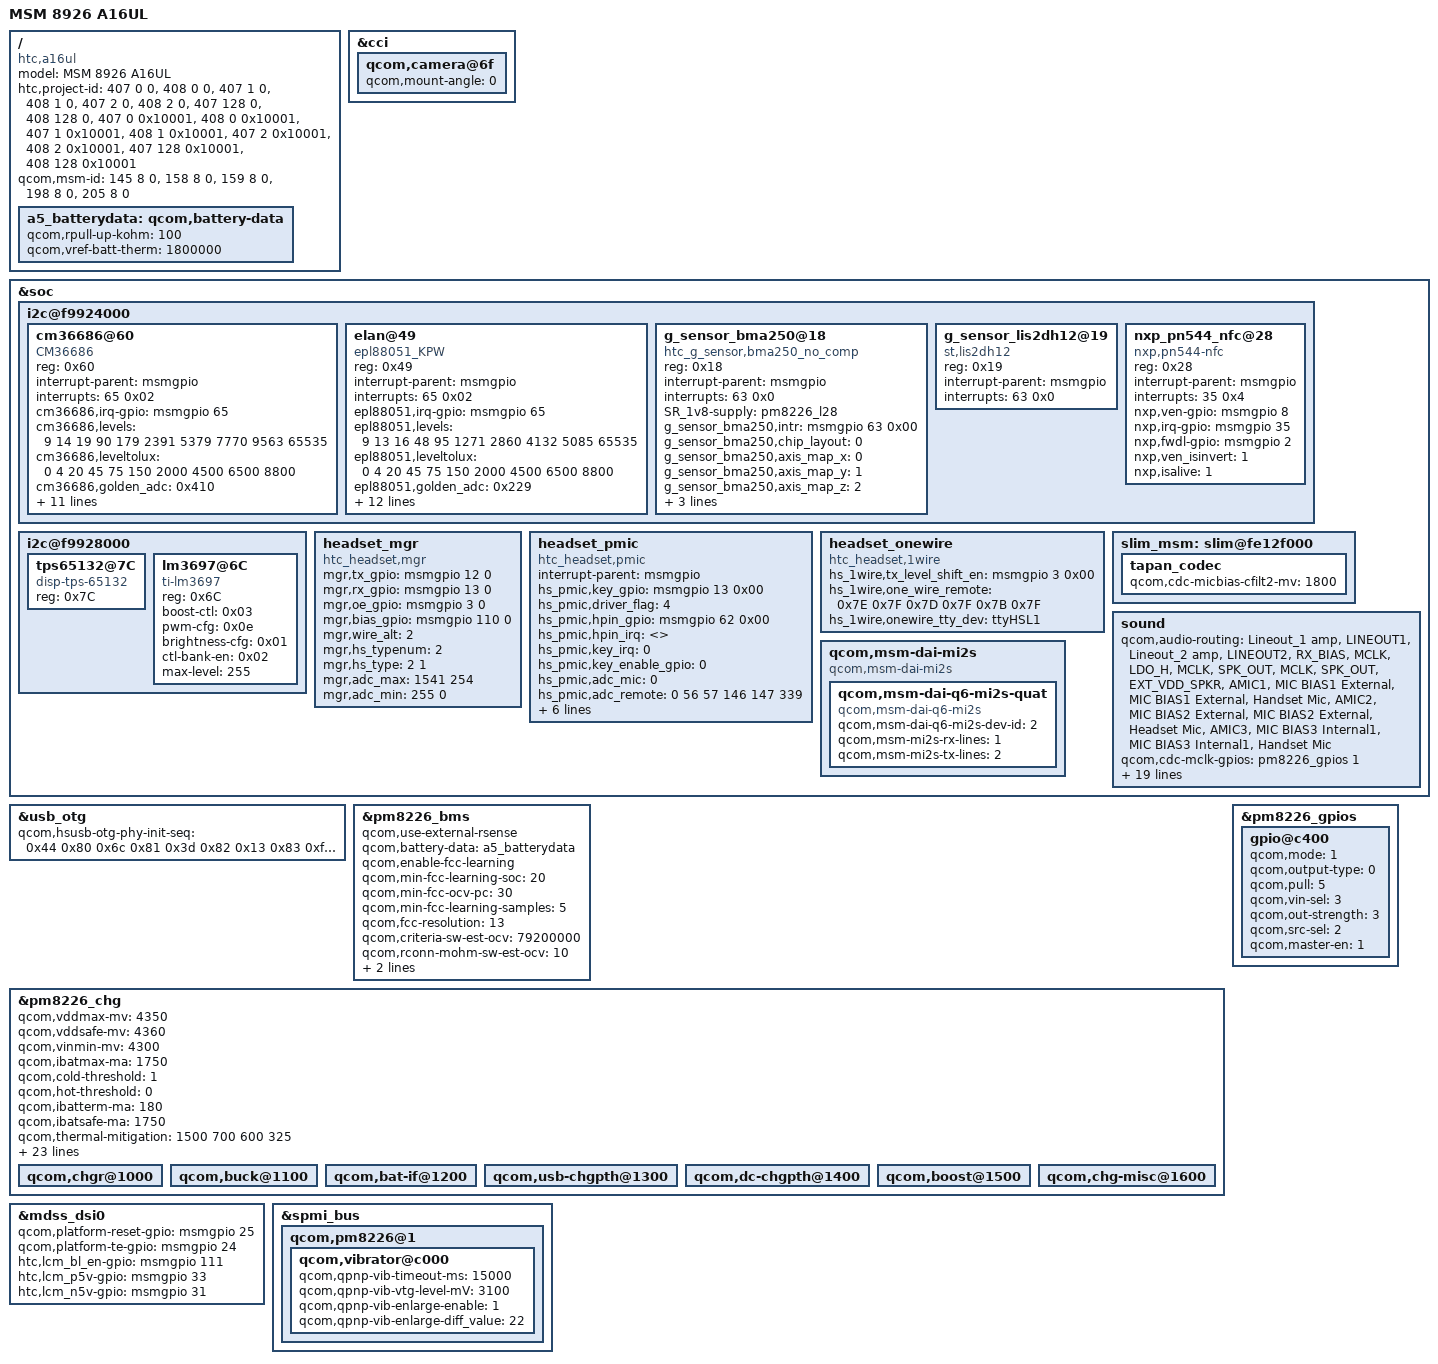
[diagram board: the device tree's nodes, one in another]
/* Copyright (c) 2013, The Linux Foundation. All rights reserved.
 *
 * This program is free software; you can redistribute it and/or modify
 * it under the terms of the GNU General Public License version 2 and
 * only version 2 as published by the Free Software Foundation.
 *
 * This program is distributed in the hope that it will be useful,
 * but WITHOUT ANY WARRANTY; without even the implied warranty of
 * MERCHANTABILITY or FITNESS FOR A PARTICULAR PURPOSE.  See the
 * GNU General Public License for more details.
 */

/dts-v1/;
/include/ "msm8926.dtsi"
/include/ "msm8226-720p-mtp.dtsi"
/*/include/ "msm-ncp6924.dtsi"*/
/include/ "dsi-panel-a16.dtsi"
/include/ "msm8226-a5ul-storage.dtsi"
/include/ "msm8926-touch-a16-config.dtsi"
/include/ "msm8926-flashlight-a16.dtsi"
/include/ "msm8926-key-a16.dtsi"
/include/ "msm8926-a16ul-twl80125-regulator.dtsi"

/ {
	model = "MSM 8926 A16UL";
	compatible = "htc,a16ul", "qcom,msm8926-mtp", "qcom,msm8926", "qcom,mtp";
	htc,project-id = <407 0 0>, <408 0 0>, <407 1 0>, <408 1 0>, <407 2 0>, <408 2 0>, <407 128 0>, <408 128 0>, <407 0 0x10001>, <408 0 0x10001>, <407 1 0x10001>, <408 1 0x10001>, <407 2 0x10001>, <408 2 0x10001>, <407 128 0x10001>, <408 128 0x10001>;  /* <pid hw-version reserve> */
	qcom,msm-id = <145 8 0>,
		      <158 8 0>,
		      <159 8 0>,
		      <198 8 0>,
		      <205 8 0>;
};

&cci {
	/* Rotate rear camera to 0 degrees */
	qcom,camera@6f {
	qcom,mount-angle = <0>;
	};
};

&soc {
	i2c@f9924000 {
		cm36686@60 {
			compatible = "CM36686";
			reg = <0x60>;
			// MSM8909: msm_gpio, MSM8928: msmgpio
			interrupt-parent = <&msmgpio>;
			interrupts = <65 0x02>;
			interrupt-names = "cm36686";
			cm36686,irq-gpio = <&msmgpio 65 0x00>;
			cm36686,levels = <9 14 19 90 179 2391 5379 7770 9563 65535>;
			cm36686,leveltolux = <0 4 20 45 75 150 2000 4500 6500 8800>;
			cm36686,golden_adc = <0x410>;
			cm36686,cm36686_slave_address = <0x60>;
			cm36686,ps1_thd_set = <0x15>;
			cm36686,ps1_thd_no_cal = <0xAAA>;
			cm36686,dynamical_threshold = <1>;
			cm36686,dark_level = <3>;
			cm36686,ps_duty = <0>;
			cm36686,ps_pers = <1>;
			cm36686,ps_it = <7>;
			cm36686,ps_hd = <0>;
			cm36686,ps_led_current = <2>;
			SR_2v85-supply = <&pm8226_l19>;
		};
	};

	i2c@f9924000 {
		elan@49 {
			compatible = "epl88051_KPW";
			reg = <0x49>;
			/* MSM8909: msm_gpio; MSM8928: msmgpio */
			interrupt-parent = <&msmgpio>;
			interrupts = <65 0x02>;
			interrupt-names = "epl88051";
			epl88051,irq-gpio = <&msmgpio 65 0x00>;
			epl88051,levels = <9 13 16 48 95 1271 2860 4132 5085 65535>;
			epl88051,leveltolux = <0 4 20 45 75 150 2000 4500 6500 8800>;
			epl88051,golden_adc = <0x229>;
			epl88051,epl88051_slave_address = <0x49>;
			epl88051,ps1_thd_set = <0x15>;
			epl88051,ps_th_add = <0x1F4>;
			epl88051,ps1_thd_no_cal = <0xAAA>;
			epl88051,dynamical_threshold = <1>;
			epl88051,dark_level = <3>;
			epl88051,ps_duty = <0x06>; //PS_FILTER(ps 64 cycle)
			epl88051,ps_pers = <0x00>; //PS_PERSIST(1 frame)
			epl88051,ps_it = <0x18>; //PS_INTEG (INTEG=80)
			epl88051,ps_hd = <0>;
			epl88051,ps_led_current = <0x00>; //PS_IR_DRIVE(200mA)
			SR_2v85-supply = <&pm8226_l19>;
	        };
	};

	i2c@f9924000 {
		g_sensor_bma250@18 {
			compatible = "htc_g_sensor,bma250_no_comp";
			reg = <0x18>;
			interrupt-parent = <&msmgpio>;
			interrupts = <63 0x0>;
			SR_1v8-supply = <&pm8226_l28>;
			g_sensor_bma250,intr        = <&msmgpio 63 0x00>;
			g_sensor_bma250,chip_layout = <0>;
			g_sensor_bma250,axis_map_x  = <0>;
			g_sensor_bma250,axis_map_y  = <1>;
			g_sensor_bma250,axis_map_z  = <2>;
			g_sensor_bma250,negate_x    = <0>;
			g_sensor_bma250,negate_y    = <0>;
			g_sensor_bma250,negate_z    = <0>;
			//pinctrl-names = "bma255_acc_init";
			//pinctrl-0 = <&bma255_acc_int>;
		};

		g_sensor_lis2dh12@19 {
            compatible = "st,lis2dh12";
            reg = <0x19>;
            interrupt-parent = <&msmgpio>;
            interrupts = <63 0x0>;
        };
	};

	i2c@f9924000 {
		nxp_pn544_nfc@28 {
			compatible = "nxp,pn544-nfc";
			reg = <0x28>;
			interrupt-parent = <&msmgpio>;
			interrupts = <35 0x4>;
			nxp,ven-gpio = <&msmgpio 8 0x00>;
			nxp,irq-gpio = <&msmgpio 35 0x00>;
			nxp,fwdl-gpio = <&msmgpio 2 0x00>;
			nxp,ven_isinvert = <1>;
			nxp,isalive = <1>;
		};
	};

	i2c@f9928000 {
		tps65132@7C {
			compatible = "disp-tps-65132";
			reg = <0x7C>;
		};

		lm3697@6C {
			compatible = "ti-lm3697";
			reg = <0x6C>;
			boost-ctl = <0x03>; /* 24V, 1MHz */
			pwm-cfg = <0x0e>; /* control B PWM enable */
			brightness-cfg = <0x01>; /* linear mapping */
			ctl-bank-en = <0x02>; /* control B enable */
			max-level = <255>;
		};
	};

	headset_mgr {
		compatible   = "htc_headset,mgr";
		mgr,tx_gpio  = <&msmgpio 12 0>;
		mgr,rx_gpio  = <&msmgpio 13 0>;
		mgr,oe_gpio  = <&msmgpio 3 0>;
		mgr,bias_gpio  = <&msmgpio 110 0>;
		mgr,wire_alt = <2>;
		mgr,hs_typenum   = <2>;
		mgr,hs_type      = <2 1>;
		mgr,adc_max      = <1541 254>; // <1557 254>, 1% tolerance
		mgr,adc_min      = <255 0>;
	};

	headset_pmic {
		compatible = "htc_headset,pmic";
		interrupt-parent = <&msmgpio>;
		hs_pmic,key_gpio 	= <&msmgpio 13 0x00>;
		hs_pmic,driver_flag     = <4>;
		hs_pmic,hpin_gpio       = <&msmgpio 62 0x00>;
		hs_pmic,hpin_irq        = <>;
		hs_pmic,key_irq         = <0>;
		hs_pmic,key_enable_gpio = <0>;
		hs_pmic,adc_mic         = <0>;
		hs_pmic,adc_remote      = <0 56 57 146 147 339>;
		hs_pmic,adc_channel	= <17>;		//P_MUX2_1_1
		hs_pmic,adc_mpp         = <0>;
		hs_pmic,adc_amux        = <0>;
		hs_pmic,hs_controller   = <0>;
		hs_pmic,hs_switch       = <0>;
		qcom,headset-vadc	= <&pm8226_vadc>;
	};

	headset_onewire {
		compatible = "htc_headset,1wire";
		hs_1wire,tx_level_shift_en = <&msmgpio 3 0x00>;
		hs_1wire,one_wire_remote = <0x7E 0x7F 0x7D 0x7F 0x7B 0x7F>;
		hs_1wire,onewire_tty_dev = "ttyHSL1";
	};

/*Audio config start*/
	slim_msm: slim@fe12f000 {
		tapan_codec {
			qcom,cdc-micbias-cfilt2-mv = <1800>;
		};
	};

	sound {
		qcom,audio-routing =
			"Lineout_1 amp", "LINEOUT1",
			"Lineout_2 amp", "LINEOUT2",
			"RX_BIAS", "MCLK",
			"LDO_H", "MCLK",
			"SPK_OUT", "MCLK",
			"SPK_OUT", "EXT_VDD_SPKR",
			"AMIC1", "MIC BIAS1 External",
			"MIC BIAS1 External", "Handset Mic",
			"AMIC2", "MIC BIAS2 External",
			"MIC BIAS2 External", "Headset Mic",
			"AMIC3", "MIC BIAS3 Internal1",
			"MIC BIAS3 Internal1", "Handset Mic";

		qcom,cdc-mclk-gpios = <&pm8226_gpios 1 0>;
		qcom,cdc-vdd-spkr-gpios = <>;

		qcom,prim-auxpcm-gpio-clk  = <>;
		qcom,prim-auxpcm-gpio-sync = <>;
		qcom,prim-auxpcm-gpio-din  = <>;
		qcom,prim-auxpcm-gpio-dout = <>;
		qcom,sec-auxpcm-gpio-clk  = <>;
		qcom,sec-auxpcm-gpio-sync = <>;
		qcom,sec-auxpcm-gpio-din  = <>;
		qcom,sec-auxpcm-gpio-dout = <>;

		mi2s-gpio-sck   = <&msmgpio 49 0>;
		mi2s-gpio-ws    = <&msmgpio 50 0>;
		mi2s-gpio-sda0  = <&msmgpio 51 0>;
		mi2s-gpio-sda1  = <&msmgpio 52 0>;
		mi2s-afe-portid = <0x1004>;

		rcv-gpio-sel    = <&msmgpio 0 0>;
		rcv-gpio-en     = <&msmgpio 69 0>;

                htc,spk-gpio-5v-en  = <&pm8226_gpios 5 0>;
		htc,aud-digital-mic-en = <0>;
		htc,aud-24b-en = <1>;
	};

	qcom,msm-dai-mi2s {
		compatible = "qcom,msm-dai-mi2s";
		qcom,msm-dai-q6-mi2s-quat {
			compatible = "qcom,msm-dai-q6-mi2s";
			qcom,msm-dai-q6-mi2s-dev-id = <2>;
			qcom,msm-mi2s-rx-lines = <1>;
			qcom,msm-mi2s-tx-lines = <2>;
		};
	};
/*Audio config end*/

/*	i2c@f9928000 {
		twl80125-regulator@50 {
			regulator-buck1 {
				twl,init-microvolt = <1200000>;
			};
			regulator-buck2 {
				twl,init-microvolt = <1200000>;
			};
			regulator-ldo1 {
				twl,init-microvolt = <2800000>;
			};
			regulator-ldo2 {
				twl,init-microvolt = <2850000>;
			};
			regulator-ldo3 {
				twl,init-microvolt = <1800000>;
			};
			regulator-ldo5 {
				twl,init-microvolt = <2800000>;
			};
		};
	};*/
};

&usb_otg {
    qcom,hsusb-otg-phy-init-seq =
            <0x44 0x80 0x6c 0x81 0x3d 0x82 0x13 0x83 0xffffffff>;
};

&pm8226_bms {
	qcom,use-external-rsense;
	qcom,battery-data = <&a5_batterydata>;
	qcom,enable-fcc-learning;
	qcom,min-fcc-learning-soc = <20>;
	qcom,min-fcc-ocv-pc = <30>;
	qcom,min-fcc-learning-samples = <5>;
	qcom,fcc-resolution = <13>;
	qcom,criteria-sw-est-ocv = <79200000>;
	qcom,rconn-mohm-sw-est-ocv = <10>;
	qcom,enable-sw-ocv-in-eoc = <1>;
	qcom,enable-batt-full-fake-ocv = <1>;
	status = "ok";
};

&pm8226_chg {
	qcom,vddmax-mv = <4350>;
	qcom,vddsafe-mv = <4360>;
	qcom,vinmin-mv = <4300>;
	qcom,ibatmax-ma = <1750>;
	qcom,cold-threshold = <1>;
	qcom,hot-threshold = <0>;
	qcom,ibatterm-ma = <180>;
	qcom,ibatsafe-ma = <1750>;
	qcom,thermal-mitigation = <1500 700 600 325>;
	qcom,cool-bat-decidegc = <0>;
	qcom,cool-bat-mv = <4350>;
	qcom,ibatmax-warm-ma = <1750>;
	qcom,warm-bat-decidegc = <480>;
	qcom,warm-bat-mv = <4100>;
	qcom,ibatmax-cool-ma = <1750>;
	qcom,vbatdet-delta-mv = <50>;
	qcom,resume-soc = <99>;
	qcom,tchg-mins = <960>;
	qcom,batt-hot-percentage = <25>;
	qcom,batt-cold-percentage = <80>;
	qcom,chg-vadc = <&pm8226_vadc>;
	qcom,chg-adc_tm = <&pm8226_adc_tm>;
	qcom,eoc-ibat-thre-ma = <50>;
	qcom,is-embeded-batt = <1>;
	htc,external-ovpfet-gpio = <&msmgpio 114 0>;
	htc,external-ovpfet-temp-ok-rext = <130>;
	htc,external-ovpfet-temp-cool-rext = <122>;
	htc,external-ovpfet-cool-decidegc = <100>;
	qcom,stored-pre-delta-vddmax-mv= <(-1)>;
	qcom,stored-batt-magic-num= <(-1)>;

	status = "ok";
	qcom,charging-disabled;
	qcom,enable-qct-adjust-vddmax;

	qcom,chgr@1000 {
		status = "ok";
	};

	qcom,buck@1100 {
		status = "ok";
	};

	qcom,bat-if@1200 {
		status = "ok";
	};

	qcom,usb-chgpth@1300 {
		status = "ok";
	};

	qcom,dc-chgpth@1400 {
		status = "ok";
	};

	qcom,boost@1500 {
		status = "ok";
	};

	qcom,chg-misc@1600 {
		status = "ok";
	};
};

/ {
	a5_batterydata: qcom,battery-data {
		qcom,rpull-up-kohm = <100>;
		qcom,vref-batt-therm = <1800000>;

			/include/ "batterydata-a5-id1.dtsi"
			/include/ "batterydata-a5-id2.dtsi"
			/include/ "batterydata-a5-unknown-id.dtsi"
	};
};

&mdss_dsi0 {
	qcom,platform-reset-gpio = <&msmgpio 25 0>;
	qcom,platform-te-gpio = <&msmgpio 24 0>;
	htc,lcm_bl_en-gpio = <&msmgpio 111 0>;
	htc,lcm_p5v-gpio = <&msmgpio 33 0>;
	htc,lcm_n5v-gpio = <&msmgpio 31 0>;
};

&spmi_bus {
	qcom,pm8226@1 {
		qcom,vibrator@c000 {
			qcom,qpnp-vib-timeout-ms = <15000>;
			qcom,qpnp-vib-vtg-level-mV = <3100>;
			qcom,qpnp-vib-enlarge-enable = <1>;
			qcom,qpnp-vib-enlarge-diff_value = <22>;
			status = "okay";
		};
	};
};

&pm8226_gpios {

        gpio@c400 { /* GPIO 5 */
                qcom,mode = <1>;
                qcom,output-type = <0>;
                qcom,pull = <5>;
                qcom,vin-sel = <3>;
                qcom,out-strength = <3>;
                qcom,src-sel = <2>;
                qcom,master-en = <1>;
        };
};

